# PN73xxAU register map
File version: 2
CPU: CM0 r0p0, little endian, no MPU, no FPU, 2 interrupt priority bits
Registers are 32-bit, read-write, reset 0x0 unless marked. A register's access mark holds for its fields unless they carry their own. Offsets are from the block's base; [hi:lo] are bit positions; <NAME> marks a mode.

## CLIF (part 1 of 2) — Contactless Interface Frontend
Base 0x40004000
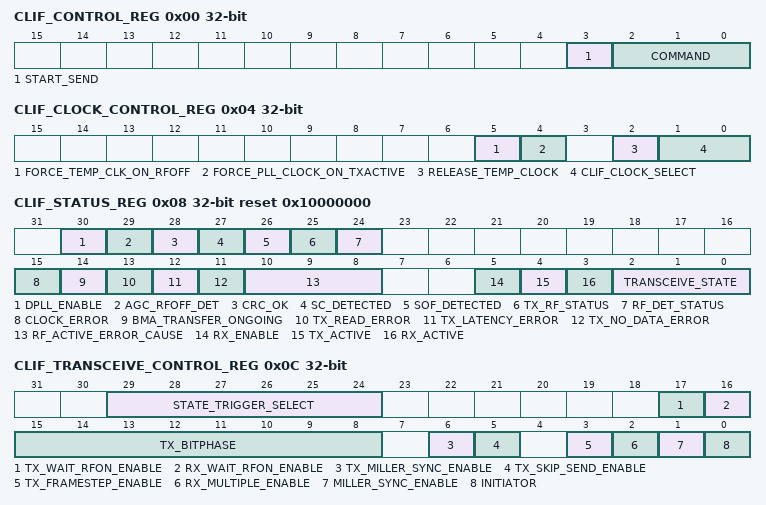
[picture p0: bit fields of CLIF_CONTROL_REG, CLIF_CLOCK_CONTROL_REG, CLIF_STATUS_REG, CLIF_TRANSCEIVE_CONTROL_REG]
0x00 CLIF_CONTROL_REG — Main control register for CLIF digital
  [3] START_SEND — Set to logic 1. the data transmission is started. Note: This bit is only valid in combination with the Transceive command Note: If TxWait is set to a value other than zero the TxWait period configured must be expired as well that the transmission starts Note: As soon as the transmission started this bit is cleared by HW.
  [2:0] COMMAND — This registers hold the command bits 0* IDLE/StopCom Command. stops all ongoing communication and set the CLIF to IDLE mode. reset value 1 Transmit command. starts a transmission immediately 2 Receive command. enables the receiver. After end of reception the bits are clear and IDLE 3 Transceive command. initiates a transceive cycle. Note: Depending on the value of the Initiator bit a transmission is started or the receiver is enabled Note: The transceive command does not finish automatically. It stays in the transceive cycle until stopped via the IDLE/StopCom command 4 KeepCommand command. This command does not change the content of the command register and might be used in case other bits in the register are to be changed 5 LoopBack command. This command is for test purposes only. It starts a transmission and at the same enables the receiver. 6 - 7 Reserved: Do not use this settings 1
0x04 CLIF_CLOCK_CONTROL_REG — CLIF digital clock control register
  [5] FORCE_TEMP_CLK_ON_RFOFF — If set to 1 upon RFOFF event the clock is always switched to temporary-clock no matter if pll-clock is available.
  [4] FORCE_PLL_CLOCK_ON_TXACTIVE — If set to 1 clock is automatically switched to DPLL clock for transmission
  [2] RELEASE_TEMP_CLOCK wo — Setting this register bit to 1 will release the temporary clock and switch back to functional mode. Afterwards it is cleared by HW. Note: In normal operation this bit must not be set.
  [1:0] CLIF_CLOCK_SELECT — This register controlls the source of the CLIF clock (13.56MHz contactless frequency clock) 0* Automatic clock selection. The source of the clock is automatically chosen depending on the RF-Field status. If an external RF-Field is detected the RF-clock is chosen otherwise the PLL-clock (indipendent if it is available) 1 Force RF-clock. RF-clock is chosen as source. not automatic switching is performed. 2 Force PLL-clock. PLL-clock is chosen as source. not automatic switching is performed. 3 Reserved. Do not use this setting
0x08 CLIF_STATUS_REG ro reset 0x10000000 — CLIF digital status register
  [30] DPLL_ENABLE — This bit indicates that the DPLL Controler has enabled the DPLL (RF on RF frequency ok PLL locked)
  [29] AGC_RFOFF_DET — This bit indicates than the AGC has detected the external RF-Field was switched off while transmitting in SL-ALM mode. Note: Only valid if the detection mode is enabled with the register bit-field AGC_RF_DETECT_SEL
  [28] CRC_OK — This bit indicates the status of the actual CRC calculation. If 1 the CRC is correct. meaning the CRC register has the value 0 or the residue value if inverted CRC is used. Note: This flag should only by evaluated at the end of a communication
  [27] SC_DETECTED — Status signal indicating that a subcarrier is detected
  [26] SOF_DETECTED — Status signal indicating that a SOF has been detected
  [25] TX_RF_STATUS — If set to 1 this bit indicates that the drivers are turned on. meaning an RF-Field is created by the device itself.
  [24] RF_DET_STATUS — If set to 1 this bit indicates that an external RF-Field is detected by the rf level detectors (after digital filtering)
  [15] CLOCK_ERROR — If set to 1 CLIF is operating on the temporary clock.
  [14] BMA_TRANSFER_ONGOING — Status signal from BufferManager to indicate that a transfer is actually ongoing.
  [13] TX_READ_ERROR — This error flag is set to 1 if for an ongoing transmission data is not copied from RAM in time (BMA encountered read error) and therefor the transmission is aborted Note: This case should not happen in normal operation
  [12] TX_LATENCY_ERROR — This error flag is set to 1. if for an ongoing transmission data is not availabe in time (BMA latency to big) and therefor the transmission is aborted. Note: This case should not happen in normal operation
  [11] TX_NO_DATA_ERROR — This error flag is set to 1. in case a transmission is started but no data is available (register NumBytesToSend == 0).
  [10:8] RF_ACTIVE_ERROR_CAUSE — This status flag indicates the cause of an NFC-Active error. Note: This bits are only valid when the RF_ACTIVE_ERROR_IRQ is raised and will be cleared as soon as the bit TX_RF_ENABLE is set to 1. 0* No Error. reset value 1 External field was detected on within TIDT timing 2 External field was detected on within TADT timing 3 No external field was detected within TADT timings 4 Peer did switch off RFField without but no Rx event was raised (no data received) 5 - 7 Reserved
  [5] RX_ENABLE — This bit indicates if the RxDecoder is enalbed. If 1 the RxDecoder was enabled by the Transceive Unit and is now ready for data reception
  [4] TX_ACTIVE — This bit indicates activity of the TxEncoder. If 1 a transmission is ongoing otherwise the TxEncoder is in idle state.
  [3] RX_ACTIVE — This bit indicates activity of the RxDecoder. If 1 a data reception is ongoing. otherwise the RxDecoder is in idle state.
  [2:0] TRANSCEIVE_STATE — This registers hold the command bits 0* IDLE state 1 WaitTransmit state 2 Transmitting state 3 WaitReceive state 4 WaitForData state 5 Receiving state 6 LoopBack state 7 reserved
0x0C CLIF_TRANSCEIVE_CONTROL_REG — Transceive control register
  [29:24] STATE_TRIGGER_SELECT — Register to select the state to trigger the STATE_CHANGE_IRQ flag. Each bit of the bit field enables one state - several states are possible. Note: If all bits are 0 no IRQ is triggered. xxxxx1 IDLE state enabled to trigger IRQ xxxx1x WaitTransmit state enabled to trigger IRQ xxx1xx Transmitting state enabled to trigger IRQ xx1xxx WaitReceive state enabled to trigger IRQ x1xxxx WaitForData state enabled to trigger IRQ 1xxxxx Receiving state enabled to trigger IRQ
  [17] TX_WAIT_RFON_ENABLE — If set to 1 the TxWait guard time will be started when the own RF-Field is switched on. Note: In default configuration the TxWait guard time is started at the end of reception. This feature is intended to be used for NFC-Active communication
  [16] RX_WAIT_RFON_ENABLE — If set to 1 the RxWait guard time will be started when the own RF-Field is switched off and an external RF-Field was detected. Note: In default configuration the RxWait guard time is started at the end of transmission. This feature is intended to be used for NFC-Active communication
  [15:8] TX_BITPHASE — Defines the number of 13.56MHz cycles used for adjustment of tx_wait to meet the FDT.
  [6] TX_MILLER_SYNC_ENABLE — If set to 1 guard time is synchronized to miller envelope for transmission. Used for AGC.
  [5] TX_SKIP_SEND_ENABLE — If set to 1 not transmission is started after tx_wait is expired and START_SEND was set Note: The bit is cleared by HW when the WaitReceive state is entered.
  [3] TX_FRAMESTEP_ENABLE — If set to 1. at every start of transmission. each byte of data is sent in a seperate frame. SOF and EOF is appended to the data byte according to the framing settings. After one byte is transmitted. the TxEncoder waits for a new start trigger to continue with the next byte.
  [2] RX_MULTIPLE_ENABLE — If this bit is set to 1. the receiver is re-activated after the end of a reception. A statusbyte is written to the RAM containing all relevant status information of the frame. Note: Data in RAM is word aligned therefore empty bytes of a data Word in RAM are padded with 0x00 bytes. SW has to calculate the correct address for the following frame.
  [1] MILLER_SYNC_ENABLE — If set to one miller pulse synchronisation is enabled. Note: TX_BITPHASE is used to adjust the prescaler of the guard timer. Note: This bit is set by HW when TypeA protocol is detected in automatic mode detection.
  [0] INITIATOR — Set to 1. the CLIF is configured for initiator mode. Depending on this setting the behavior of the transceive command is different
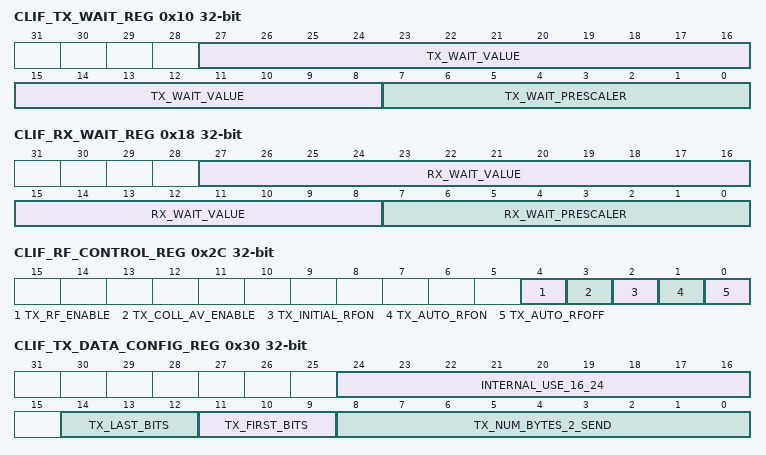
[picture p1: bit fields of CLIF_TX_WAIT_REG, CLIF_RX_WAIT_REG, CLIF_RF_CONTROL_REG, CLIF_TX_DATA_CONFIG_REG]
0x10 CLIF_TX_WAIT_REG — Transceive TxWait register
  [27:8] TX_WAIT_VALUE — Defines the tx_wait timer reload value. Note: If set to 00000h the tx_wait guard time is disabled Note: This bit is set by HW a protocol is detected in automatic mode detection
  [7:0] TX_WAIT_PRESCALER — Defines the prescaler reload value for the tx_wait timer. Note: This bit is set by HW a protocol is detected in automatic mode detection
0x14 CLIF_TX_TIMESLOT_SEL_REG — Transceive TimeSlot register
  [31:0] INTERNAL_USE_0_31 — Internal Use
0x18 CLIF_RX_WAIT_REG — Transceive RxWait register
  [27:8] RX_WAIT_VALUE — Defines the rx_wait timer reload value. Note: If set to 00000h the rx_wait guard time is disabled
  [7:0] RX_WAIT_PRESCALER — Defines the prescaler reload value for the rx_wait timer.
0x24 CLIF_TX_WATERLEVEL_REG — BufferManager TxWaterlevel register
  [7:0] TX_WATERLEVEL — Defines a warning level to indicate that TX_WATERLEVEL number of words were already transmitted in the actual frame. When this level is reached the corresponding IRQ is set. Note: 0 disables the waterlevel Note: In case a header byte offset is set the waterlevel refers to word fetched from RAM
0x28 CLIF_RX_WATERLEVEL_REG — BufferManager TxWaterlevel register
  [7:0] RX_WATERLEVEL — Defines a warning level to indicate that RX_WATERLEVEL number of words were already received in the actual frame. When this level is reached the corresponding IRQ is set. Note: 0 disables the waterlevel
0x2C CLIF_RF_CONTROL_REG — RFControl control register
  [4] TX_RF_ENABLE — Set to 1. turning on the driver in reader or active mode is requested. Note: According to the setting of InitialRFOn. AutoRFOn and CAOn the driver is turned after a defined time and depended on the presence of an external RF field. Note: In case of an RFActiveError this bit is cleared by HW
  [3] TX_COLL_AV_ENABLE — Set to 1.enables automatic collision avoidance. See ISO18092 for more details.
  [2] TX_INITIAL_RFON — Set to 1. the drivers are automatically turned on when no external field is present. In the case an external field is detected. the turning on the drivers is delay until the external field vanishes. Note: The driver on procedure must be triggered by setting TX_RF_ENABLE. Note: This bit is reset to 0 as soon as the drivers turned on.
  [1] TX_AUTO_RFON — Set to 1. the drivers are automatically turned on after a before present external field vanished. Note: The driver on procedure must be triggered by setting TX_RF_ENABLE.
  [0] TX_AUTO_RFOFF — Set to 1. the drivers are automatically turned off after data is transmitted.
0x30 CLIF_TX_DATA_CONFIG_REG — TxEncoder config register
  [24:16] INTERNAL_USE_16_24 — Internal Use
  [14:12] TX_LAST_BITS — Defines how many bits of the last data byte to be sent. If set to 000b all bits of the last data byte are sent. Note: Bits are skipped at the end of the byte
  [11:9] TX_FIRST_BITS — Defines how many bits of the first data byte to be sent. If set to 000b all bits of the last data byte are sent. Note: Bits are skipped at the beginning of the byte
  [8:0] TX_NUM_BYTES_2_SEND — Defines the number of bytes to be transmit. The maximum number of bytes is 260 (0x104). If the Transmission Of Data Is Enabled (TX_DATA_ENABLE) and TX_NUM_BYTES_2_SEND is zero. then a NO_DATA_ERROR occurs.
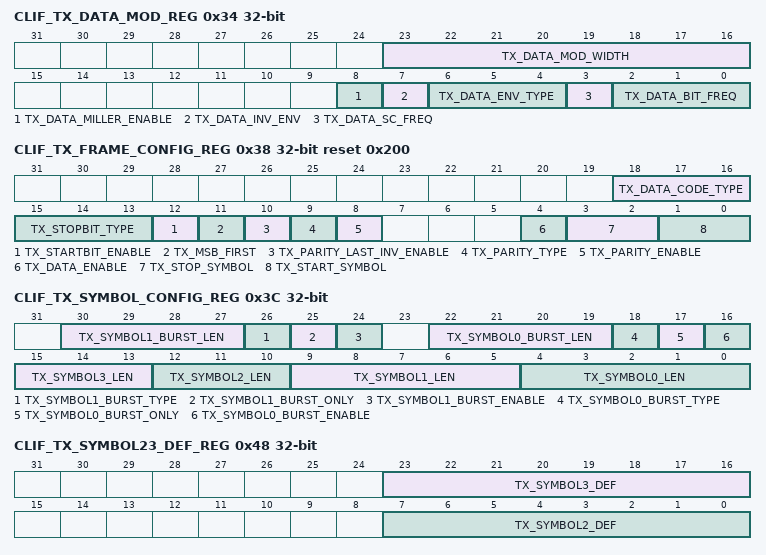
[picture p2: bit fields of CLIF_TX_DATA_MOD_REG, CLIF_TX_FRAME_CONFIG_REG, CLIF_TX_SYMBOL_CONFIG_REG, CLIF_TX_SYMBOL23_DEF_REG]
0x34 CLIF_TX_DATA_MOD_REG — TxEncoder config register
  [23:16] TX_DATA_MOD_WIDTH — Specifies the length of a pulse for sending data with miller pulse modulation enabled. The length is given by the number of carrier clocks + 1.
  [8] TX_DATA_MILLER_ENABLE — If set to 1 pulse modulation is applied according to modified miller coding
  [7] TX_DATA_INV_ENV — If set to 1 the output envelope is inverted
  [6:4] TX_DATA_ENV_TYPE — Specifies the type of envelope used for transmission of data packets. The selected envelope type is applied to the pseudo bit stream. 000b Direct output 001b Manchester code 010b Manchster code with subcarrier 011b BPSK 100b RZ (pulse of half bit length at beginning of second half of bit) 101b RZ (pulse of half bit length at beginning of bit) 110b Manchester tupple coding 111b RFU
  [3] TX_DATA_SC_FREQ — Specifies the frequency of the subcarrier. 0 424 kHz 1 848 kHz
  [2:0] TX_DATA_BIT_FREQ — Specifies the frequency of the bit-stream. 000b -> 1.695 MHz. 001b -> Reserved. 010b -> 26 kHz. 011b -> 53 kHz. 100b -> 106 kHz. 101b -> 212 kHz. 110b -> 424 kHz. 111b -> 848 kHz.
0x38 CLIF_TX_FRAME_CONFIG_REG reset 0x200 — TxEncoder config register
  [18:16] TX_DATA_CODE_TYPE — Specifies the type of encoding of data to be used 000b No special code 001b 1 out of 4 code [I-Code SLI] 010b 1 out of 256 code [I-Code SLI] 011b Pulse interval encoding (PIE) [I-Code EPC-V2] 100b 2bit tuple code (intended only for test purpose) 101-111b Reserved
  [15:13] TX_STOPBIT_TYPE — Enables the stop bit (logic 1 ) and extra guard time (logic 1 ). The value 0 disables transmission of stop-bits. 000b no stop-bit. no EGT 001b stop-bit. no EGT 010b stop-bit + 1 EGT 011b stop-bit + 2 EGT 100b stop-bit + 3 EGT 101b stop-bit + 4 EGT 110b stop-bit + 5 EGT 111b stop-bit + 6 EGT
  [12] TX_STARTBIT_ENABLE — If set to 1. a start-bit (logic 0 ) will be send
  [11] TX_MSB_FIRST — If set to 1. data bytes are interpreted MSB first for data transmission
  [10] TX_PARITY_LAST_INV_ENABLE — If set to 1. the parity bit of last sent data byte is inverted
  [9] TX_PARITY_TYPE — Defines the type of the parity bit 0 Even Parity is calculated 1 Odd parity is calculated
  [8] TX_PARITY_ENABLE — If set to 1. a parity bit is calculated and appended to each byte transmitted. If the Transmission Of Data Is Enabled and TX_NUM_BYTES_2_SEND is zero. then a NO_DATA_ERROR occurs.
  [4] TX_DATA_ENABLE — If set to 1. transmission of data is enabled otherwise only symbols are tranmitted.
  [3:2] TX_STOP_SYMBOL — Defines which pattern symbol is sent as frame stop-symbol 00b No symbol is sent 01b Symbol1 is sent 10b Symbol2 is sent 11b Symbol3 is sent
  [1:0] TX_START_SYMBOL — Defines which symbol pattern is sent as frame start-symbol 00b No symbol pattern is sent 01b Symbol0 is sent 10b Symbol1 is sent 11b Symbol2 is sent
0x3C CLIF_TX_SYMBOL_CONFIG_REG — TxEncoder config register
  [30:27] TX_SYMBOL1_BURST_LEN — Specifies the number of bits issued for symbol 1 burst. The 3 bits encode a range from 8 to 256 bit length: 0000b 8 bit 0001b 12 bit 0010b 16 bit 0011b 24 bit 0100b 32 bit 0101b 40 bit 0110b 48 bit 0111b 64 bit 1000b 80 bit 1001b 96 bit 1010b 112 bit 1011b 128 bit 1100b 160 bit 1101b 192 bit 1110b 224 bit 1111b 256 bit
  [26] TX_SYMBOL1_BURST_TYPE — Specifies the type of the burst of Symbol1 (logical zero / logical one)
  [25] TX_SYMBOL1_BURST_ONLY — If set to 1. Symbol1 consists only of a burst and no symbol pattern
  [24] TX_SYMBOL1_BURST_ENABLE — If set to 1. the burst of Symbol0 of the length defined in bit field SYMBOL1_BURST_LEN is enabled
  [22:19] TX_SYMBOL0_BURST_LEN — Specifies the number of bits issued for symbol 0 burst. The 3 bits encode a range from 8 to 256 bit length: 0000b 8 bit 0001b 12 bit 0010b 16 bit 0011b 24 bit 0100b 32 bit 0101b 40 bit 0110b 48 bit 0111b 64 bit 1000b 80 bit 1001b 96 bit 1010b 112 bit 1011b 128 bit 1100b 160 bit 1101b 192 bit 1110b 224 bit 1111b 256 bit
  [18] TX_SYMBOL0_BURST_TYPE — Specifies the type of the burst of Symbol0 (logical zero / logical one)
  [17] TX_SYMBOL0_BURST_ONLY — If set to 1. Symbol0 consists only of a burst and no symbol pattern
  [16] TX_SYMBOL0_BURST_ENABLE — If set to 1. the burst of Symbol0 of the length defined in bit field SYMBOL0_BURST_LEN is enabled
  [15:13] TX_SYMBOL3_LEN — Specifies the number of valid bits of the symbol definition of Symbol3. The range is from 1 bit (value 0000) to 8 bit (value 111)
  [12:10] TX_SYMBOL2_LEN — Specifies the number of valid bits of the symbol definition of Symbol2. The range is from 1 bit (value 0000) to 8bit (value 111)
  [9:5] TX_SYMBOL1_LEN — Specifies the number of valid bits of the symbol definition of Symbol1. The range is from 1 bit (value 0000) to 28 bit (value 11011)
  [4:0] TX_SYMBOL0_LEN — Specifies the number of valid bits of the symbol definition of Symbol0. The range is from 1 bit (value 0000) to 28 bit (value 11011)
0x40 CLIF_TX_SYMBOL0_DEF_REG — TxEncoder config register
  [27:0] TX_SYMBOL0_DEF — Pattern definition for Symbol0
0x44 CLIF_TX_SYMBOL1_DEF_REG — TxEncoder config register
  [27:0] TX_SYMBOL1_DEF — Pattern definition for Symbol1
0x48 CLIF_TX_SYMBOL23_DEF_REG — TxEncoder config register
  [23:16] TX_SYMBOL3_DEF — Pattern definition for Symbol3
  [7:0] TX_SYMBOL2_DEF — Pattern definition for Symbol2
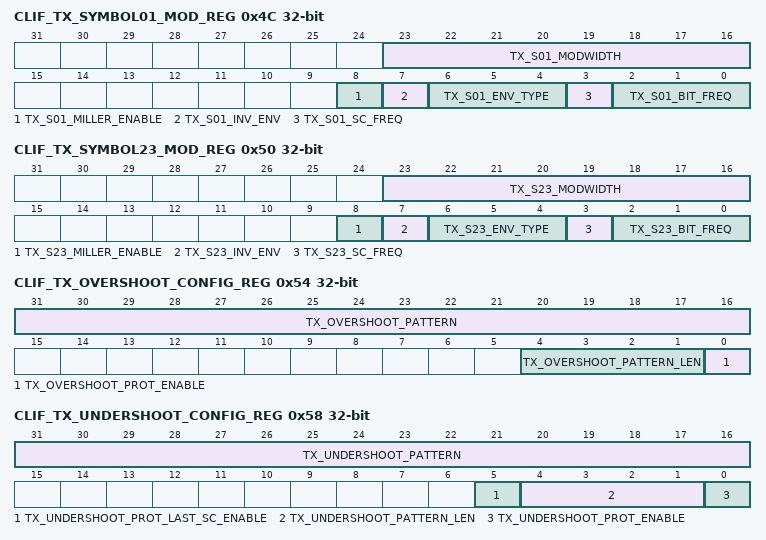
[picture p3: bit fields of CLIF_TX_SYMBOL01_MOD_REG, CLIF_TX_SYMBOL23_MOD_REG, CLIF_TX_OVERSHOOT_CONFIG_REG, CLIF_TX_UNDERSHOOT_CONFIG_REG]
0x4C CLIF_TX_SYMBOL01_MOD_REG — TxEncoder config register
  [23:16] TX_S01_MODWIDTH — Specifies the length of a pulse for sending data of symbol 0/1. The length is given by the number of carrier clocks + 1.
  [8] TX_S01_MILLER_ENABLE — If set to 1. pulse modulation is applied according to modified miller coding.
  [7] TX_S01_INV_ENV — If set to 1. the output envelope is inverted.
  [6:4] TX_S01_ENV_TYPE — Specifies the type of envelope used for transmission of data packets. The selected envelope type is applied to the pseudo bit stream. 000b Direct output 001b Manchester code 010b Manchster code with subcarrier 011b BPSK 100b RZ (pulse of half bit length at beginning of second half of bit) 101b RZ (pulse of half bit length at beginning of bit) 110b Manchester tupple 111b RFU
  [3] TX_S01_SC_FREQ — Specifies the frequency of the subcarrier. 0 424 kHz 1 848 kHz
  [2:0] TX_S01_BIT_FREQ — Specifies the frequency of the bit-stream. 000b -> 1.695 MHz. 001b -> Reserved. 010b -> 26 kHz. 011b -> 53 kHz. 100b -> 106 kHz. 101b -> 212 kHz. 110b -> 424 kHz. 111b -> 848 kHz.
0x50 CLIF_TX_SYMBOL23_MOD_REG — TxEncoder config register
  [23:16] TX_S23_MODWIDTH — Specifies the length of a pulse for sending data of symbol 2/3. The length is given by the number of carrier clocks + 1.
  [8] TX_S23_MILLER_ENABLE — If set to 1 pulse modulation is applied according to modified miller coding.
  [7] TX_S23_INV_ENV — If set to 1 the output envelope is inverted.
  [6:4] TX_S23_ENV_TYPE — Specifies the type of envelope used for transmission of data packets. The selected envelope type is applied to the pseudo bit stream. 000b Direct output 001b Manchester code 010b Manchster code with subcarrier 011b BPSK 100b RZ (pulse of half bit length at beginning of second half of bit) 101b RZ (pulse of half bit length at beginning of bit) 110b Manchester tupple 111b RFU
  [3] TX_S23_SC_FREQ — Specifies the frequency of the subcarrier. 0 424 kHz 1 848 kHz
  [2:0] TX_S23_BIT_FREQ — Specifies the frequency of the bit-stream. 000b -> 1.695 MHz. 001b -> Reserved. 010b -> 26 kHz. 011b -> 53 kHz. 100b -> 106 kHz. 101b -> 212 kHz. 110b -> 424 kHz. 111b -> 848 kHz.
0x54 CLIF_TX_OVERSHOOT_CONFIG_REG — TxEncoder overshot prevention config register
  [31:16] TX_OVERSHOOT_PATTERN — Overshoot pattern which is transmitted after each rising egde.
  [4:1] TX_OVERSHOOT_PATTERN_LEN — Defines length of the overshoot prevention pattern (value +1). The pattern is applied starting from the LSB of the defined pattern. all other bits are ignored.
  [0] TX_OVERSHOOT_PROT_ENABLE — If set to 1. the overshoot protection is enabled.
0x58 CLIF_TX_UNDERSHOOT_CONFIG_REG — TxEncoder undershot prevention config register
  [31:16] TX_UNDERSHOOT_PATTERN — Undershoot pattern which is transmitted after each falling egde.
  [5] TX_UNDERSHOOT_PROT_LAST_SC_ENABLE — This mode activates the undershoot prevention circuit only for the last sub-carrier cycle for card-mode transmission - Note: The bit TX_UNDERSHOOT_PROT_ENABLE must not be set in this mode.
  [4:1] TX_UNDERSHOOT_PATTERN_LEN — Defines length of the undershoot prevention pattern (value +1). The pattern is applied starting from the LSB of the defined pattern. all other bits are ignored.
  [0] TX_UNDERSHOOT_PROT_ENABLE — If set to 1. the undershoot protection is enabled
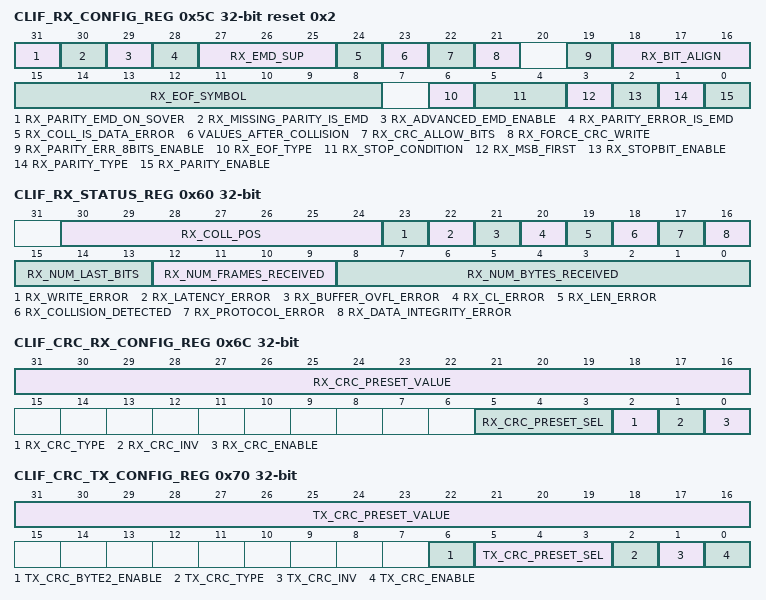
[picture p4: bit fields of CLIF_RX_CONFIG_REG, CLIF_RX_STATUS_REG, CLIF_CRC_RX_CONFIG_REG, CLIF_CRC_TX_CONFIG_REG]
0x5C CLIF_RX_CONFIG_REG reset 0x2 — RxDecoder registers
  [31] RX_PARITY_EMD_ON_SOVER — if set decision if EMD due to parity error is taken at sover (depending on frame length)
  [30] RX_MISSING_PARITY_IS_EMD — if set a missing parity bit in the 4th byte is treated as EMD (EMD options 3/4)
  [29] RX_ADVANCED_EMD_ENABLE — if set new EMD options are enabled
  [28] RX_PARITY_ERROR_IS_EMD — If set to 1 a parity error in the 3rd/4th byte (depending on RX_EMD_SUP setting) is interpreted as an EMD error. Otherwise it is interpreted as a parity error.
  [27:25] RX_EMD_SUP — Defines EMD suppression mechanism 000 Off 001 EMD suppression according to ISO14443 010 EMD suppression according to NFC Forum (with respect to the first 3 characters) 011 EMD suppression according to NFC Forum (with respect to the first 4characters) 100 EMD suppression according to NFC Forum (with respect to the first 4characters all valid frames <4 bytes are ignored) 101-111 RFU
  [24] RX_COLL_IS_DATA_ERROR — If set to 1. a collision is treated as a data integrity error (especially for ISO14443-4)
  [23] VALUES_AFTER_COLLISION — This bit defined the value of bits received after a collision occured. 0* All received bits after a collision will be cleared. 1 All received bits after a collision keep their value.
  [22] RX_CRC_ALLOW_BITS — Set to 1. a frame with less than one byte length is writtten to ram. when the CRC is enabled otherwise it is discarted.
  [21] RX_FORCE_CRC_WRITE — Set to 1. the received CRC byte(s) are written to ram. In normal operation (if this bit is set to 0) CRC bytes are only checked and removed from the data stream.
  [19] RX_PARITY_ERR_8BITS_ENABLE — if set parity error is detected when only 8 bits in last byte received
  [18:16] RX_BIT_ALIGN — RxAlign defines the bit position within the byte for the first bit received. Further received bits are stored at the following bit positions.
  [15:8] RX_EOF_SYMBOL — This value defines the pattern of the EOF symbol. Note: All bits are clear upon enabling of the receiver is the automatic mode detection is enabled. If in such a case an ISO14443A communication is detected bit0 is set by the mod-detector.
  [6] RX_EOF_TYPE — Defines the EOF handling 0 EOF as defined in the register field RX_EOF_SYMBOL is expected. 1 EOF as defined in ISO14443B is expected.
  [5:4] RX_STOP_CONDITION — This bit field defines the condition to stop a reception. Note: This bit is set by the mod-detector if automatic mode detection is enabled and the corresponding communication is detected. 00b Reception is stopped only if end of data communication is detected by the signal processing 01b Reception is stopped upon reception of the EOF pattern selected by the register field RX_EOF_TYPE and RX_EOF_SYMBOL Note: This value is set by the mod-detector if a ISO14443A or ISO14443B communication is detected 10b Reception is stopped on detection of an incorrect parity bit. 11b Recption is stopped if the number of received bytes reaches the defined frame length (which extracted from the first data-byte received). Note: This value is set by the mod-detector if a Felica communication is detected
  [3] RX_MSB_FIRST — If set to 1. data bytes are interpreted MSB first for reception
  [2] RX_STOPBIT_ENABLE — Set to 1. a stop-bit is expected and will be checked and extracted from data stream. Note: The stop-bit is not configurable and fixed to a logic 1. Note: This bit is set by the mod-detector if automatic mode detection is enabled and ISO14443B communication is detected.
  [1] RX_PARITY_TYPE — Defines which type of the parity-bit is used Note: This bit is set by the mod-detector if automatic mode detection is enabled and ISO14443A communication is detected. 0 Even parity calculation is used 1 Odd parity calculation is used
  [0] RX_PARITY_ENABLE — If set to 1. a parity-bit for each byte is expected. will be extracted from data stream and checked for correctness. In case the parity-bit is incorrect. the RX_DATA_INTEGRITY_ERROR flag is set. Nevertheless the reception is continued. Note: This bit is set by the mod-detector if automatic mode detection is enabled and ISO14443A communication is detected.
0x60 CLIF_RX_STATUS_REG ro — RxDecoder registers
  [30:24] RX_COLL_POS — These bits show the bit position of the first detected collision in a received frame (only databits are interpreted). Note: These bits shall only be interpreted in passive communication mode at 106 kbit/s or ISO14443A /MIFARE® reader / writer or ICode SLI reader / writer mode if bit CollPosValid is set to 1. Note: If RX_ALIGN is set to a value different to 0.this value is included in the RX_COLL_POS.
  [23] RX_WRITE_ERROR — This error flag is set to 1. if for an ongoing reception data is not copied to RAM in time (BMA encountered write error) and therefor the reception is aborted Note: This case should not happen in normal operation
  [22] RX_LATENCY_ERROR — This error flag is set to 1. if for an ongoing reception data is not copied to RAM in time (BMA latency to big) and therefor the reception is aborted Note: This case should not happen in normal operation
  [21] RX_BUFFER_OVFL_ERROR — This flag is set to 1 when the number of received bytes exceeds the size of the RxBuffer
  [20] RX_CL_ERROR — General contactless error. is a combination of data integrity. protocol and collision error
  [19] RX_LEN_ERROR — This flag is set to 1. if RxMultiple is activate and the LEN byte indicates more than 28 bytes
  [18] RX_COLLISION_DETECTED — This flag is set to 1. when a collision has accured. The position of the first collision is shown in the register RX_COLLPOS
  [17] RX_PROTOCOL_ERROR — This flag is set to 1. when a protocol error has accured. A protocol error can be a wrong stopbit. a missing or wrong ISO14443B EOF or SOF or a wrong number of received data bytes. Note: When a protocol error is detected. data reception is stopped. Note: The flag is automatically cleared at start of next reception.
  [16] RX_DATA_INTEGRITY_ERROR — This flag is set to 1. if a data integrity error has been detected. Possible caused can be a wrong parity or a wrong CRC. Note: On a data integrity error the reception is continued Note: The flag is automatically cleared at start of next reception. Note: If a reversed parity bit is a stop criteria. the flag is not set to 1 in case of a wrong parity.
  [15:13] RX_NUM_LAST_BITS — Defines the number of valid bits of the last data byte received in bit-oriented communications. If zero the whole byte is valid.
  [12:9] RX_NUM_FRAMES_RECEIVED — Indicates the number of frames received. The value is updated when the RxIRQ is raised. Note: This bit field is only valid when the RxMultiple is active (bit RX_MULTIPLE_ENABLE set)
  [8:0] RX_NUM_BYTES_RECEIVED — the number of bytes received. The value is valid when the RxIRQ is raised until the receiver is enabled again.
0x6C CLIF_CRC_RX_CONFIG_REG — CRC registers
  [31:16] RX_CRC_PRESET_VALUE — Arbitrary preset value for the Rx-Decoder CRC calculation.
  [5:3] RX_CRC_PRESET_SEL — Preset value of the CRC register for the Rx-Decoder. For a CRC calculation using 5bits only the LSByte is used. 000b* 0000h reset value Note that this configuration is set by the Mode detector for FeliCa. 001b 6363h Note that this configuration is set by the Mode detector for ISO14443 type A. 010b A671h 011b FFFFh Note that this configuration is set by the Mode detector for ISO14443 type B. 100b 0012h 101b E012h 110b RFU 111b Use arbitrary preset value RX_CRC_PRESET_VALUE
  [2] RX_CRC_TYPE — Controls the type of CRC calulation for the Rx-Decoder 0* 16bit CRC calculation. reset value 1 5bit CRC calculation
  [1] RX_CRC_INV — Controls the comparison of the CRC checksum for the Rx-Decoder 0* Not inverted CRC value: 0000h reset value Note that this nit is cleared by the Mode detector for ISO14443 type A and FeliCa. 1 Inverted CRC value: F0B8h Note that this bit is set by the Mode detector for ISO14443 type B.
  [0] RX_CRC_ENABLE — If set. the Rx-Decoder will check the CRC for correctness. Note that this bit is set by the Mode Detector. when ISO14443 type B. or FeliCa (212 or 424kBd) is detected.
0x70 CLIF_CRC_TX_CONFIG_REG — CRC registers
  [31:16] TX_CRC_PRESET_VALUE — Arbitrary preset value for the Tx-Encoder CRC calculation.
  [6] TX_CRC_BYTE2_ENABLE — If set. the CRC is calculated from the 2nd byte onwards (intended for HID). Note that this option is used in the Tx-Encoder.
  [5:3] TX_CRC_PRESET_SEL — Preset value of the CRC register for the Tx-Encoder. For a CRC calculation using 5bits. only the LSByte is used. 000b* 0000h. reset value 001b 6363h 010b A671h 011b FFFFh 100b 0012h 101b E012h 110b RFU 111b Use arbitrary preset value TX_CRC_PRESET_VALUE
  [2] TX_CRC_TYPE — Controls the type of CRC calulation for the Tx-Encoder 0* 16bit CRC calculation. reset value 1 5bit CRC calculation
  [1] TX_CRC_INV — Controls the sending of an inverted CRC value by the Tx-Encoder 0* Not inverted CRC checksum. reset value 1 Inverted CRC checksum
  [0] TX_CRC_ENABLE — If set to one. the Tx-Encoder will compute and transmit a CRC.
0x74 CLIF_CRC_DATA_REG ro — CRC registers
  [15:0] INTERNAL_USE_0_15 — Internal Use
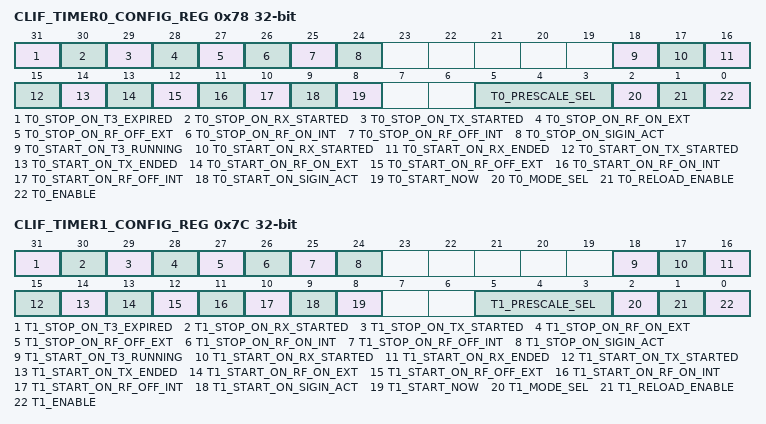
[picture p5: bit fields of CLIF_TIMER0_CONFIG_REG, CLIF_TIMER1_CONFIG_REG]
0x78 CLIF_TIMER0_CONFIG_REG — CLTimer register
  [31] T0_STOP_ON_T3_EXPIRED — T0_STOP_EVENT: If set the timer T0 is stopped when timer T3 raises its expiration flag.
  [30] T0_STOP_ON_RX_STARTED — T0_STOP_EVENT: If set. the timer T0 is stopped when a data reception begins (1st bit is received).
  [29] T0_STOP_ON_TX_STARTED — T0_STOP_EVENT: If set. the timer T0 is stopped when a data transmission begins.
  [28] T0_STOP_ON_RF_ON_EXT — T0_STOP_EVENT: If set. the timer T0 is stopped when the external RF field is detected.
  [27] T0_STOP_ON_RF_OFF_EXT — T0_STOP_EVENT: If set. the timer T0 is stopped when the external RF field vanishes.
  [26] T0_STOP_ON_RF_ON_INT — T0_STOP_EVENT: If set. the timer T0 is stopped when the internal RF field is turned on.
  [25] T0_STOP_ON_RF_OFF_INT — T0_STOP_EVENT: If set. the timer T0 is stopped when the internal RF field is turned off.
  [24] T0_STOP_ON_SIGIN_ACT — T0_STOP_EVENT: If set. the timer T0 is stopped when an activity on SigIn is detected.
  [18] T0_START_ON_T3_RUNNING — T0_START_EVENT: If set the timer T0 is started when the timer T3 starts running.
  [17] T0_START_ON_RX_STARTED — T0_START_EVENT: If set. the timer T0 is started when a data reception begins (1st bit is received).
  [16] T0_START_ON_RX_ENDED — T0_START_EVENT: If set. the timer T0 is started when a data reception ends.
  [15] T0_START_ON_TX_STARTED — T0_START_EVENT: If set. the timer T0 is started when a data transmission begins.
  [14] T0_START_ON_TX_ENDED — T0_START_EVENT: If set. the timer T0 is started when a data transmission ends.
  [13] T0_START_ON_RF_ON_EXT — T0_START_EVENT: If set. the timer T0 is startedwhen the external RF field is detected.
  [12] T0_START_ON_RF_OFF_EXT — T0_START_EVENT: If set. the timer T0 is started when the external RF field is not detected any more.
  [11] T0_START_ON_RF_ON_INT — T0_START_EVENT: If set. the timer T0 is started when an internal RF field is turned on.
  [10] T0_START_ON_RF_OFF_INT — T0_START_EVENT:If set. the timer T0 is started when an internal RF field is turned off.
  [9] T0_START_ON_SIGIN_ACT — T0_START_EVENT: If set. the timer T0 is started when an activity on SigIn is detected.
  [8] T0_START_NOW — T0_START_EVENT: If set. the timer T0 is started immediatly.
  [5:3] T0_PRESCALE_SEL — Controls frequency/period of the timer T0 when the prescaler is activated in T0_MODE_SEL. 000b* 6.78MHz counter 001b 3.39MHz counter 010b 1.70MHz counter 011b 848kHz counter 100b 424kHz counter 101b 212kHz counter 110b 106kHz counter 111b 53kHz counter
  [2] T0_MODE_SEL — Configuration of the timer T0 clock. 0b* Prescaler is disabled: the timer frequency matches CLIF clock frequency (13.56MHz). 1b Prescaler is enabled: the timer operates on the prescaler signal frequency (chosen by T0_PRESCALE_SEL).
  [1] T0_RELOAD_ENABLE — If set to 0.the timer T0 will stop on expiration. 0* After expiration the timer T0 will stop counting. i.e.. remain zero. reset value. 1 After expiration the timer T0 will reload its preset value and continue counting down.
  [0] T0_ENABLE — Enables the timer T0
0x7C CLIF_TIMER1_CONFIG_REG — CLTimer register
  [31] T1_STOP_ON_T3_EXPIRED — T1_STOP_EVENT: If set. the timer T1 is stopped when timer T3 raises its expiration flag.
  [30] T1_STOP_ON_RX_STARTED — T1_STOP_EVENT: If set. the timer T1 is stopped when a data reception begins (1st bit is received).
  [29] T1_STOP_ON_TX_STARTED — T1_STOP_EVENT: If set. the timer T1 is stopped when a data transmission begins.
  [28] T1_STOP_ON_RF_ON_EXT — T1_STOP_EVENT: If set. the timer T1 is stopped when the external RF field is detected.
  [27] T1_STOP_ON_RF_OFF_EXT — T1_STOP_EVENT: If set. the timer T1 is stopped when the external RF field vanishes.
  [26] T1_STOP_ON_RF_ON_INT — T1_STOP_EVENT: If set. the timer T1 is stopped when the internal RF field is turned on.
  [25] T1_STOP_ON_RF_OFF_INT — T1_STOP_EVENT: If set. the timer T1 is stopped when the internal RF field is turned off.
  [24] T1_STOP_ON_SIGIN_ACT — T1_STOP_EVENT: If set. the timer T1 is stopped when an activity on SigIn is detected.
  [18] T1_START_ON_T3_RUNNING — T1_START_EVENT: If set. the timer T1 is started when timer T3 has started.
  [17] T1_START_ON_RX_STARTED — T1_START_EVENT: If set. the timer T1 is started when a data reception begins (1st bit is received).
  [16] T1_START_ON_RX_ENDED — T1_START_EVENT: If set. the timer T1 is started when a data reception ends.
  [15] T1_START_ON_TX_STARTED — T1_START_EVENT: If set. the timer T1 is started when a data transmission begins.
  [14] T1_START_ON_TX_ENDED — T1_START_EVENT: If set. the timer T1 is started when a data transmission ends.
  [13] T1_START_ON_RF_ON_EXT — T1_START_EVENT: If set. the timer T1 is startedwhen the external RF field is detected.
  [12] T1_START_ON_RF_OFF_EXT — T1_START_EVENT: If set. the timer T1 is started when the external RF field is not detected any more.
  [11] T1_START_ON_RF_ON_INT — T1_START_EVENT: If set. the timer T1 is started when an internal RF field is turned on.
  [10] T1_START_ON_RF_OFF_INT — T1_START_EVENT:If set. the timer T1 is started when an internal RF field is turned off.
  [9] T1_START_ON_SIGIN_ACT — T1_START_EVENT: If set. the timer T1 is started when an activity on SigIn is detected.
  [8] T1_START_NOW — T1_START_EVENT: If set. the timer T1 is started immediatly.
  [5:3] T1_PRESCALE_SEL — Controls frequency/period of the timer T1 when the prescaler is activated by T1_MODE_SEL. 000b* 6.78MHz counter 001b 3.39MHz counter 010b 1.70MHz counter 011b 848kHz counter 100b 424kHz counter 101b 212kHz counter 110b 106kHz counter 111b 53kHz counter
  [2] T1_MODE_SEL — If set. the timer T1 is started the prescaler for the timer T1 is enabled. 0* Prescaler is disabled: the timer frequency matches CLIF clock frequency (13.56MHz). 1 Prescaler is enabled: the timer operates on the prescaler signal frequency (chosen by T1_PRESCALE_SEL).
  [1] T1_RELOAD_ENABLE — If set to 0.the timer T1 will stop on expiration. 0* After expiration the timer T1 will stop counting. i.e.. remain zero. reset value. 1 After expiration the timer T1 will reload its preset value and continue counting down.
  [0] T1_ENABLE — Enables the timer T1
